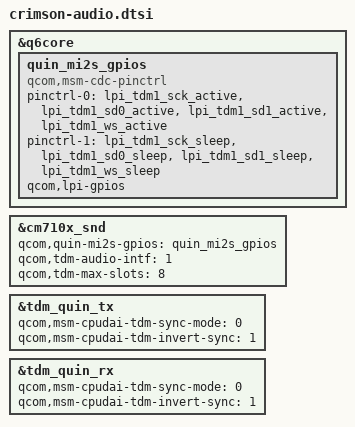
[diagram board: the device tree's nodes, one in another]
// SPDX-License-Identifier: GPL-2.0
#include "vendor-base/qcom/kona-lpi.dtsi"

&q6core {
	quin_mi2s_gpios: quin_mi2s_gpios {
		compatible = "qcom,msm-cdc-pinctrl";
		pinctrl-names = "aud_active", "aud_sleep";
		pinctrl-0 = <&lpi_tdm1_sck_active
			&lpi_tdm1_sd0_active
			&lpi_tdm1_sd1_active
			&lpi_tdm1_ws_active>;
		pinctrl-1 = <&lpi_tdm1_sck_sleep
			&lpi_tdm1_sd0_sleep
			&lpi_tdm1_sd1_sleep
			&lpi_tdm1_ws_sleep>;
		qcom,lpi-gpios;
	};
};

&cm710x_snd {
	qcom,quin-mi2s-gpios = <&quin_mi2s_gpios>;
	qcom,tdm-audio-intf = <1>;
	qcom,tdm-max-slots = <8>;
};

&tdm_quin_tx {
	qcom,msm-cpudai-tdm-sync-mode = <0>;
	qcom,msm-cpudai-tdm-invert-sync = <1>;
};

&tdm_quin_rx {
	qcom,msm-cpudai-tdm-sync-mode = <0>;
	qcom,msm-cpudai-tdm-invert-sync = <1>;
};
